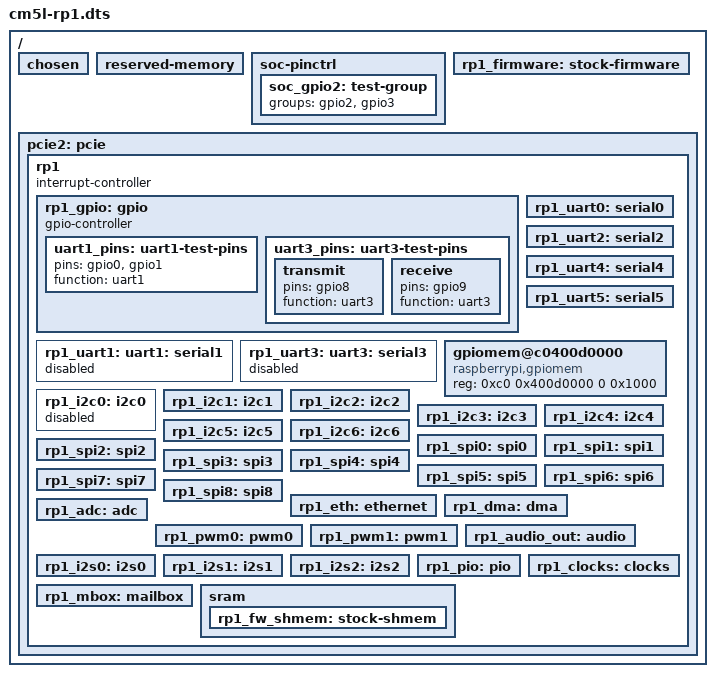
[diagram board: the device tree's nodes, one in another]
/dts-v1/;

// Synthetic tree for ownership tests. Empty labelled nodes are overlay targets.
/ {
    #address-cells = <2>;
    #size-cells = <1>;

    chosen {};
    reserved-memory {
        #address-cells = <2>;
        #size-cells = <1>;
        ranges;
    };

    soc-pinctrl {
        soc_gpio2: test-group {
            groups = "gpio2", "gpio3";
        };
    };

    rp1_firmware: stock-firmware {};

    pcie2: pcie {
        rp1: rp1 {
            #address-cells = <2>;
            #size-cells = <2>;
            #interrupt-cells = <2>;
            interrupt-controller;

            rp1_gpio: gpio {
                gpio-controller;
                #gpio-cells = <2>;

                uart1_pins: uart1-test-pins {
                    pins = "gpio0", "gpio1";
                    function = "uart1";
                };

                uart3_pins: uart3-test-pins {
                    transmit {
                        pins = "gpio8";
                        function = "uart3";
                    };
                    receive {
                        pins = "gpio9";
                        function = "uart3";
                    };
                };
            };

            rp1_uart0: serial0 {};
            rp1_uart1: uart1: serial1 {
                status = "disabled";
            };
            rp1_uart2: serial2 {};
            rp1_uart3: uart3: serial3 {
                status = "disabled";
            };
            rp1_uart4: serial4 {};
            rp1_uart5: serial5 {};

            gpiomem@c0400d0000 {
                compatible = "raspberrypi,gpiomem";
                reg = <0xc0 0x400d0000 0 0x1000>;
            };

            rp1_i2c0: i2c0 {
                status = "disabled";
            };
            rp1_i2c1: i2c1 {};
            rp1_i2c2: i2c2 {};
            rp1_i2c3: i2c3 {};
            rp1_i2c4: i2c4 {};
            rp1_i2c5: i2c5 {};
            rp1_i2c6: i2c6 {};
            rp1_spi0: spi0 {};
            rp1_spi1: spi1 {};
            rp1_spi2: spi2 {};
            rp1_spi3: spi3 {};
            rp1_spi4: spi4 {};
            rp1_spi5: spi5 {};
            rp1_spi6: spi6 {};
            rp1_spi7: spi7 {};
            rp1_spi8: spi8 {};
            rp1_eth: ethernet {};
            rp1_dma: dma {};
            rp1_adc: adc {};
            rp1_pwm0: pwm0 {};
            rp1_pwm1: pwm1 {};
            rp1_audio_out: audio {};
            rp1_i2s0: i2s0 {};
            rp1_i2s1: i2s1 {};
            rp1_i2s2: i2s2 {};
            rp1_pio: pio {};
            rp1_clocks: clocks {};
            rp1_mbox: mailbox {
                #mbox-cells = <1>;
            };
            sram: sram {
                rp1_fw_shmem: stock-shmem {};
            };
        };
    };
};
